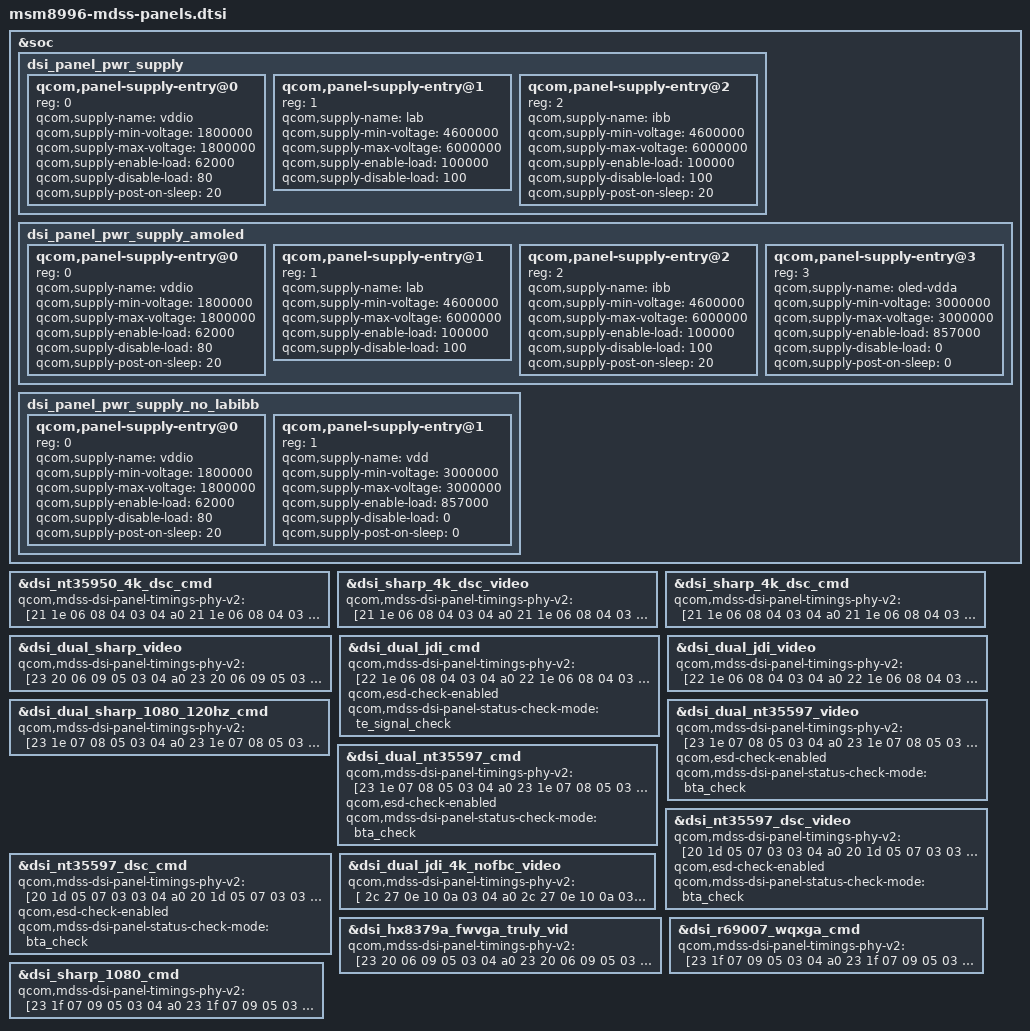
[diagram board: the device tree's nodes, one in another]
/* Copyright (c) 2015-2017, 2019, The Linux Foundation. All rights reserved.
 *
 * This program is free software; you can redistribute it and/or modify
 * it under the terms of the GNU General Public License version 2 and
 * only version 2 as published by the Free Software Foundation.
 *
 * This program is distributed in the hope that it will be useful,
 * but WITHOUT ANY WARRANTY; without even the implied warranty of
 * MERCHANTABILITY or FITNESS FOR A PARTICULAR PURPOSE.  See the
 * GNU General Public License for more details.
 */

#include "dsi-panel-sharp-dualmipi-wqxga-video.dtsi"
#include "dsi-panel-nt35597-dualmipi-wqxga-video.dtsi"
#include "dsi-panel-nt35597-dualmipi-wqxga-cmd.dtsi"
#include "dsi-panel-nt35597-dsc-wqxga-video.dtsi"
#include "dsi-panel-jdi-dualmipi-video.dtsi"
#include "dsi-panel-jdi-dualmipi-cmd.dtsi"
#include "dsi-panel-jdi-4k-dualmipi-video-nofbc.dtsi"
#include "dsi-panel-sim-video.dtsi"
#include "dsi-panel-sim-dualmipi-video.dtsi"
#include "dsi-panel-sim-cmd.dtsi"
#include "dsi-panel-sim-dualmipi-cmd.dtsi"
#include "dsi-panel-nt35597-dsc-wqxga-cmd.dtsi"
#include "dsi-panel-hx8379a-truly-fwvga-video.dtsi"
#include "dsi-panel-r69007-dualdsi-wqxga-cmd.dtsi"
#include "dsi-adv7533-1024-600p.dtsi"
#include "dsi-adv7533-720p.dtsi"
#include "dsi-adv7533-1080p.dtsi"
#include "dsi-panel-nt35950-dsc-4k-cmd.dtsi"
#include "dsi-panel-sharp-dualmipi-1080p-120hz.dtsi"
#include "dsi-panel-sharp-1080p-cmd.dtsi"
#include "dsi-panel-sharp-dsc-4k-video.dtsi"
#include "dsi-panel-toshiba-720p-video.dtsi"
#include "dsi-panel-sharp-dsc-4k-cmd.dtsi"
#include "dsi-panel-jdi-1080p-video.dtsi"

&soc {
	dsi_panel_pwr_supply: dsi_panel_pwr_supply {
		#address-cells = <1>;
		#size-cells = <0>;

		qcom,panel-supply-entry@0 {
			reg = <0>;
			qcom,supply-name = "vddio";
			qcom,supply-min-voltage = <1800000>;
			qcom,supply-max-voltage = <1800000>;
			qcom,supply-enable-load = <62000>;
			qcom,supply-disable-load = <80>;
			qcom,supply-post-on-sleep = <20>;
		};

		qcom,panel-supply-entry@1 {
			reg = <1>;
			qcom,supply-name = "lab";
			qcom,supply-min-voltage = <4600000>;
			qcom,supply-max-voltage = <6000000>;
			qcom,supply-enable-load = <100000>;
			qcom,supply-disable-load = <100>;
		};

		qcom,panel-supply-entry@2 {
			reg = <2>;
			qcom,supply-name = "ibb";
			qcom,supply-min-voltage = <4600000>;
			qcom,supply-max-voltage = <6000000>;
			qcom,supply-enable-load = <100000>;
			qcom,supply-disable-load = <100>;
			qcom,supply-post-on-sleep = <20>;
		};
	};
};

&soc {
	dsi_panel_pwr_supply_amoled: dsi_panel_pwr_supply_amoled {
		#address-cells = <1>;
		#size-cells = <0>;

		qcom,panel-supply-entry@0 {
			reg = <0>;
			qcom,supply-name = "vddio";
			qcom,supply-min-voltage = <1800000>;
			qcom,supply-max-voltage = <1800000>;
			qcom,supply-enable-load = <62000>;
			qcom,supply-disable-load = <80>;
			qcom,supply-post-on-sleep = <20>;
		};

		qcom,panel-supply-entry@1 {
			reg = <1>;
			qcom,supply-name = "lab";
			qcom,supply-min-voltage = <4600000>;
			qcom,supply-max-voltage = <6000000>;
			qcom,supply-enable-load = <100000>;
			qcom,supply-disable-load = <100>;
		};

		qcom,panel-supply-entry@2 {
			reg = <2>;
			qcom,supply-name = "ibb";
			qcom,supply-min-voltage = <4600000>;
			qcom,supply-max-voltage = <6000000>;
			qcom,supply-enable-load = <100000>;
			qcom,supply-disable-load = <100>;
			qcom,supply-post-on-sleep = <20>;
		};

		qcom,panel-supply-entry@3 {
			reg = <3>;
			qcom,supply-name = "oled-vdda";
			qcom,supply-min-voltage = <3000000>;
			qcom,supply-max-voltage = <3000000>;
			qcom,supply-enable-load = <857000>;
			qcom,supply-disable-load = <0>;
			qcom,supply-post-on-sleep = <0>;
		};
	};
};

&soc {
	dsi_panel_pwr_supply_no_labibb: dsi_panel_pwr_supply_no_labibb {
		#address-cells = <1>;
		#size-cells = <0>;

		qcom,panel-supply-entry@0 {
			reg = <0>;
			qcom,supply-name = "vddio";
			qcom,supply-min-voltage = <1800000>;
			qcom,supply-max-voltage = <1800000>;
			qcom,supply-enable-load = <62000>;
			qcom,supply-disable-load = <80>;
			qcom,supply-post-on-sleep = <20>;
		};

		qcom,panel-supply-entry@1 {
			reg = <1>;
			qcom,supply-name = "vdd";
			qcom,supply-min-voltage = <3000000>;
			qcom,supply-max-voltage = <3000000>;
			qcom,supply-enable-load = <857000>;
			qcom,supply-disable-load = <0>;
			qcom,supply-post-on-sleep = <0>;
		};
	};
};

&dsi_nt35950_4k_dsc_cmd {
	qcom,mdss-dsi-panel-timings-phy-v2 = [21 1e 06 08 04 03 04 a0
		21 1e 06 08 04 03 04 a0
		21 1e 06 08 04 03 04 a0
		21 1e 06 08 04 03 04 a0
		21 15 06 07 04 03 04 a0];
};

&dsi_sharp_4k_dsc_video {
	qcom,mdss-dsi-panel-timings-phy-v2 = [21 1e 06 08 04 03 04 a0
		21 1e 06 08 04 03 04 a0
		21 1e 06 08 04 03 04 a0
		21 1e 06 08 04 03 04 a0
		21 15 06 07 04 03 04 a0];
};

&dsi_sharp_4k_dsc_cmd {
	qcom,mdss-dsi-panel-timings-phy-v2 = [21 1e 06 08 04 03 04 a0
		21 1e 06 08 04 03 04 a0
		21 1e 06 08 04 03 04 a0
		21 1e 06 08 04 03 04 a0
		21 15 06 07 04 03 04 a0];
};

&dsi_dual_sharp_video {
	qcom,mdss-dsi-panel-timings-phy-v2 = [23 20 06 09 05 03 04 a0
			23 20 06 09 05 03 04 a0
			23 20 06 09 05 03 04 a0
			23 20 06 09 05 03 04 a0
			23 2e 06 08 05 03 04 a0];
};

&dsi_dual_jdi_cmd {
	qcom,mdss-dsi-panel-timings-phy-v2 = [22 1e 06 08 04 03 04 a0
			22 1e 06 08 04 03 04 a0
			22 1e 06 08 04 03 04 a0
			22 1e 06 08 04 03 04 a0
			22 2c 05 08 04 03 04 a0];
	qcom,esd-check-enabled;
	qcom,mdss-dsi-panel-status-check-mode = "te_signal_check";
};

&dsi_dual_jdi_video {
	qcom,mdss-dsi-panel-timings-phy-v2 = [22 1e 06 08 04 03 04 a0
			22 1e 06 08 04 03 04 a0
			22 1e 06 08 04 03 04 a0
			22 1e 06 08 04 03 04 a0
			22 2c 05 08 04 03 04 a0];
};

&dsi_dual_sharp_1080_120hz_cmd {
	qcom,mdss-dsi-panel-timings-phy-v2 = [23 1e 07 08 05 03 04 a0
			23 1e 07 08 05 03 04 a0
			23 1e 07 08 05 03 04 a0
			23 1e 07 08 05 03 04 a0
			23 18 07 08 05 03 04 a0];
};

&dsi_dual_nt35597_video {
	qcom,mdss-dsi-panel-timings-phy-v2 = [23 1e 07 08 05 03 04 a0
		23 1e 07 08 05 03 04 a0
		23 1e 07 08 05 03 04 a0
		23 1e 07 08 05 03 04 a0
		23 18 07 08 04 03 04 a0];
	qcom,esd-check-enabled;
	qcom,mdss-dsi-panel-status-check-mode = "bta_check";
};

&dsi_dual_nt35597_cmd {
	qcom,mdss-dsi-panel-timings-phy-v2 = [23 1e 07 08 05 03 04 a0
		23 1e 07 08 05 03 04 a0
		23 1e 07 08 05 03 04 a0
		23 1e 07 08 05 03 04 a0
		23 18 07 08 04 03 04 a0];
	qcom,esd-check-enabled;
	qcom,mdss-dsi-panel-status-check-mode = "bta_check";
};

&dsi_nt35597_dsc_video {
	qcom,mdss-dsi-panel-timings-phy-v2 = [20 1d 05 07 03 03 04 a0
		20 1d 05 07 03 03 04 a0
		20 1d 05 07 03 03 04 a0
		20 1d 05 07 03 03 04 a0
		20 12 05 06 03 13 04 a0];
	qcom,esd-check-enabled;
	qcom,mdss-dsi-panel-status-check-mode = "bta_check";
};

&dsi_nt35597_dsc_cmd {
	qcom,mdss-dsi-panel-timings-phy-v2 = [20 1d 05 07 03 03 04 a0
		20 1d 05 07 03 03 04 a0
		20 1d 05 07 03 03 04 a0
		20 1d 05 07 03 03 04 a0
		20 12 05 06 03 13 04 a0];
	qcom,esd-check-enabled;
	qcom,mdss-dsi-panel-status-check-mode = "bta_check";
};

&dsi_dual_jdi_4k_nofbc_video {
	qcom,mdss-dsi-panel-timings-phy-v2 = [
		2c 27 0e 10 0a 03 04 a0
		2c 27 0e 10 0a 03 04 a0
		2c 27 0e 10 0a 03 04 a0
		2c 27 0e 10 0a 03 04 a0
		2c 32 0e 0f 0a 03 04 a0];
};

&dsi_hx8379a_fwvga_truly_vid {
	qcom,mdss-dsi-panel-timings-phy-v2 = [23 20 06 09 05 03 04 a0
		23 20 06 09 05 03 04 a0
		23 20 06 09 05 03 04 a0
		23 20 06 09 05 03 04 a0
		23 2e 06 08 05 03 04 a0];
};
&dsi_r69007_wqxga_cmd {
	qcom,mdss-dsi-panel-timings-phy-v2 = [23 1f 07 09 05 03 04 a0
		23 1f 07 09 05 03 04 a0
		23 1f 07 09 05 03 04 a0
		23 1f 07 09 05 03 04 a0
		23 19 08 08 05 03 04 a0];
};

&dsi_sharp_1080_cmd {
	qcom,mdss-dsi-panel-timings-phy-v2 = [23 1f 07 09 05 03 04 a0
		23 1f 07 09 05 03 04 a0
		23 1f 07 09 05 03 04 a0
		23 1f 07 09 05 03 04 a0
		23 19 08 08 05 03 04 a0];
};
